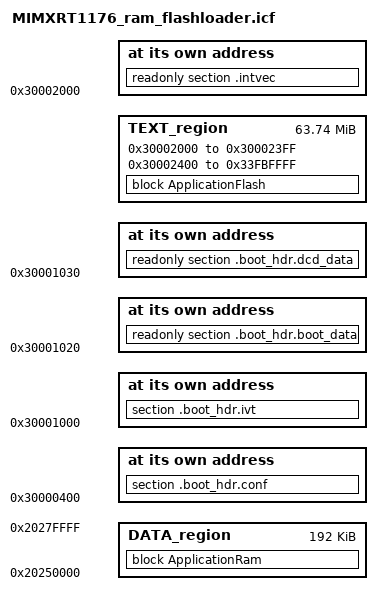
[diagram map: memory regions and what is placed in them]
/*
** ###################################################################
**     Abstract:
**         Linker file for the IAR ANSI C/C++ Compiler for ARM
**
**     Copyright 2016-2018 NXP
**
**     All rights reserved.
**
**     SPDX-License-Identifier: BSD-3-Clause
**
**
** ###################################################################
*/

define symbol m_interrupts_start       = 0x30002000;
define symbol m_interrupts_end         = 0x300023FF;

define symbol m_text_start             = 0x30002400;
if (isdefinedsymbol(__use_flash64MB__)) {
  define symbol m_text_end               = 0x33FBFFFF;
} else{
  define symbol m_text_end               = 0x30FBFFFF;
}

define symbol m_data_start             = 0x20250000;
define symbol m_data_end               = 0x2027FFFF;

define exported symbol m_boot_hdr_conf_start = 0x30000400;
define symbol m_boot_hdr_ivt_start           = 0x30001000;
define symbol m_boot_hdr_boot_data_start     = 0x30001020;
define symbol m_boot_hdr_dcd_data_start      = 0x30001030;

/* Sizes */
if (isdefinedsymbol(__stack_size__)) {
  define symbol __size_cstack__        = __stack_size__;
} else {
  define symbol __size_cstack__        = 0x1000;
}

if (isdefinedsymbol(__heap_size__)) {
  define symbol __size_heap__          = __heap_size__;
} else {
  define symbol __size_heap__          = 0;
}

define exported symbol __VECTOR_TABLE  = m_interrupts_start;
define exported symbol __VECTOR_RAM    = m_interrupts_start;
define exported symbol __RAM_VECTOR_TABLE_SIZE = 0x0;

define memory mem with size = 4G;
define region TEXT_region = mem:[from m_interrupts_start to m_interrupts_end]
                          | mem:[from m_text_start to m_text_end];
define region DATA_region = mem:[from m_data_start to m_data_end];

define block CSTACK    with alignment = 8, size = __size_cstack__   { };
define block HEAP      with alignment = 8, size = __size_heap__     { };

initialize by copy { readwrite };
initialize by copy { section .data};
initialize by copy { section .textrw };
do not initialize  { section .noinit };

define block CodeRelocate { section .textrw_init };
define block CodeRelocateRam { section .textrw };
define block ApplicationFlash { readonly, block CodeRelocate, readonly section .noinit };
define block ApplicationRam { readwrite, block CodeRelocateRam, block CSTACK, block HEAP};
place at address mem: m_interrupts_start    { readonly section .intvec };
place at address mem: m_boot_hdr_conf_start { section .boot_hdr.conf };
place at address mem: m_boot_hdr_ivt_start { section .boot_hdr.ivt };
place at address mem: m_boot_hdr_boot_data_start { readonly section .boot_hdr.boot_data };
place at address mem: m_boot_hdr_dcd_data_start { readonly section .boot_hdr.dcd_data };

keep{ section .boot_hdr.conf, section .boot_hdr.ivt, section .boot_hdr.boot_data, section .boot_hdr.dcd_data };

place in TEXT_region { block ApplicationFlash };
place in DATA_region { block ApplicationRam };
